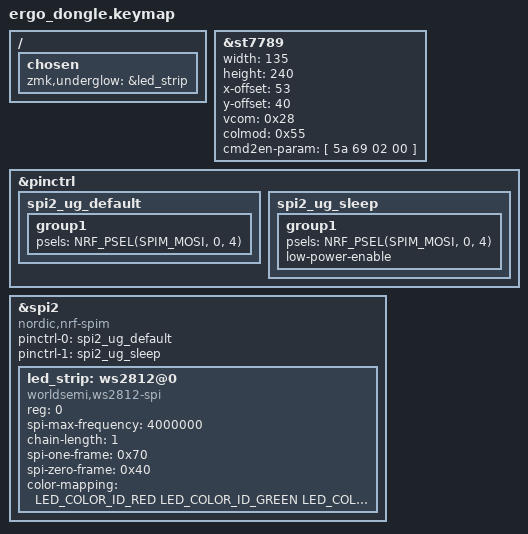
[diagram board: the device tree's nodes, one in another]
/*
 * The dongle is the central, so it runs the actual keymap (layers, combos,
 * behaviors). Rather than duplicate it, include the keyboard's keymap so
 * there's ONE source of truth - edit ergo.keymap and the dongle picks it up.
 *
 * The keymap references the matrix transform + physical layout, which are
 * provided by ergo_dongle.overlay (the dongle's own copies).
 */
#include "../ergo/ergo.keymap"

/*
 * ---- Screen geometry override for the 135x240 panel ----
 * Placed HERE (the keymap) deliberately: this file is processed AFTER YADS'
 * dongle_screen board overlay, which is where &st7789 is defined. Overriding
 * it in ergo_dongle.overlay failed because that loads BEFORE the label exists.
 *
 * YADS defaults &st7789 to a 240x280 panel; ours is 135x240. Values below are
 * a known-good config for 1.14" 135x240 ST7789V panels. If the image is
 * shifted/clipped or colors look wrong after flashing, nudge x-offset/y-offset
 * (try 52/40 or 40/53) and toggle colmod.
 */
&st7789 {
    width = <135>;
    height = <240>;
    x-offset = <53>;
    y-offset = <40>;
    vcom = <0x28>;
    colmod = <0x55>;
    cmd2en-param = [ 5a 69 02 00 ];
};

/*
 * ---- WS2812B underglow (single LED) ----
 * Placed HERE (keymap, loads LAST) deliberately: YADS' board overlay sets
 * &spi2 to "disabled", and that overlay loads AFTER ergo_dongle.overlay - so an
 * enable in the overlay would be overridden. The keymap is processed last, so
 * our status="okay" wins.
 *
 * nRF52840 serial instances: i2c0=trackpad, i2c1=YADS(ambient), spi3=display.
 * Instance 2 (spi2) is the only free one, and YADS leaves it disabled, so we
 * use it. Data pin = D4 (gpio0 4). Wire: DIN->D4, VCC->3V3, GND->GND.
 */
#include <dt-bindings/led/led.h>

&pinctrl {
    spi2_ug_default: spi2_ug_default {
        group1 {
            psels = <NRF_PSEL(SPIM_MOSI, 0, 4)>;
        };
    };
    spi2_ug_sleep: spi2_ug_sleep {
        group1 {
            psels = <NRF_PSEL(SPIM_MOSI, 0, 4)>;
            low-power-enable;
        };
    };
};

&spi2 {
    compatible = "nordic,nrf-spim";
    status = "okay";
    pinctrl-0 = <&spi2_ug_default>;
    pinctrl-1 = <&spi2_ug_sleep>;
    pinctrl-names = "default", "sleep";

    led_strip: ws2812@0 {
        compatible = "worldsemi,ws2812-spi";
        reg = <0>;
        spi-max-frequency = <4000000>;
        chain-length = <1>;
        spi-one-frame = <0x70>;
        spi-zero-frame = <0x40>;
        color-mapping = <LED_COLOR_ID_RED LED_COLOR_ID_GREEN LED_COLOR_ID_BLUE>;
    };
};

/ {
    chosen {
        zmk,underglow = &led_strip;
    };
};
